# ZB204 register map
Vendor: GS; File version: 1.2
CPU: CM3 r2p0, little endian, MPU, no FPU, VTOR, 3 interrupt priority bits
Registers are 32-bit, read-write, reset 0x0 unless marked. A register's access mark holds for its fields unless they carry their own. Offsets are from the block's base; [hi:lo] are bit positions; {n}, {i} and the like mark numbered series; 'fields as' and 'values as' point back to an identical list.

## DMAC — AMBA AHB module
Base 0x40300000
0x00 IntStatus — Interrupt Status Register
  [7:0] Intstatus — Status of the DMA interrupts after masking
0x04 IntTCStatus — Interrupt Terminal Count Status Register
  [7:0] IntTCStatus — Interrupt terminal count request status
0x08 IntTCClear — Interrupt Terminal Count Clear Register
  [7:0] IntTCClear — Terminal count request clear
0x0C IntErrorStatus — Interrupt Error Status Register
  [7:0] IntErrorStatus — Interrupt error status
0x10 IntErrClr — Interrupt Error Clear Register
  [7:0] IntErrClr — Interrupt error clear
0x14 RawIntTCStatus — Raw Interrupt Terminal Count Status Register
  [7:0] RawIntTCStatus — Status of the terminal count interrupt prior to masking
0x18 RawIntErrorStatus — Raw Error Interrupt Status Register
  [7:0] RawIntErrorStatus — Status of the error interrupt prior to masking
0x1C EnbldChns — Enabled Channel Register
  [7:0] EnabledChannels — Channel enable status
0x20 SoftBReq — ADC channel selectSoftware Burst Request Registerion Register
  [15:0] SoftBReq — Software burst request
0x24 SoftSReq — Software Single Request Register
  [15:0] SoftSReq — Software single request
0x28 SoftLBReq — Software Last Burst Request Register
  [15:0] SoftLBReq — Software last burst request
0x2C SoftLSReq — Software Last Single Request Register
  [15:0] SoftLSReq — Software last single request
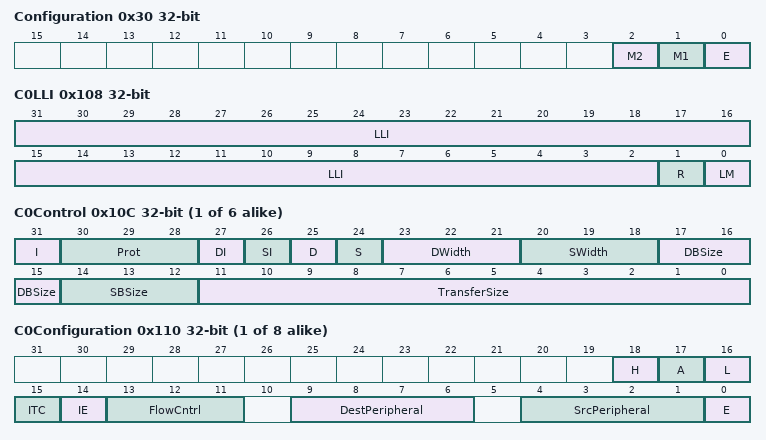
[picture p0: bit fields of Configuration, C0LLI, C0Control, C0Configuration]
0x30 Configuration
  [2] M2 — AHB Master 2 endianness configuration
  [1] M1 — AHB Master 1 endianness configuration
  [0] E — PrimeCell enable
0x34 Sync — Synchronization Register,
  [15:0] Sync — DMA synchronization logic for DMA request signals enabled or disabled
{0x100+0x20*i} C{i}SrcAddr (i=0..7) — Channel Source Address Registers,
  [31:0] SrcAddr — DMA source address
0x104 C0DestAddr — Channel Destination Address Registers,
  [31:0] DestAddr — DMA destination address
0x108 C0LLI — Channel Linked List Item Registers
  [31:2] LLI — Linked list item
  [1] R — Reserved, and must be written as 0, masked on read
  [0] LM — AHB master select for loading the next LLI
{0x10C+0x20*i} C{i}Control (i=0..5) — Channel Control Registers
  [31] I — Terminal count interrupt enable bit
  [30:28] Prot — Protection
  [27] DI — Destination increment
  [26] SI — Source increment
  [25] D — Destination AHB master select
  [24] S — Source AHB master select
  [23:21] DWidth — Destination transfer width
  [20:18] SWidth — Source transfer width
  [17:15] DBSize — Destination burst size
  [14:12] SBSize — Source burst size
  [11:0] TransferSize
{0x110+0x20*i} C{i}Configuration (i=0..7) — Channel Configuration Registers
  [18] H — Halt
  [17] A — Active
  [16] L — Lock
  [15] ITC — Terminal count interrupt mask
  [14] IE — Interrupt error mask
  [13:11] FlowCntrl — Flow control and transfer type
  [9:6] DestPeripheral — Destination peripheral
  [4:1] SrcPeripheral — Source peripheral
  [0] E — Channel enable
    0=channel disabled; 1=channel enabled
{0x104+0x20*i} C{i}DestAddr (i=1..7) — Channel Destination Address Registers
  [31:0] DestAddr — DMA destination address
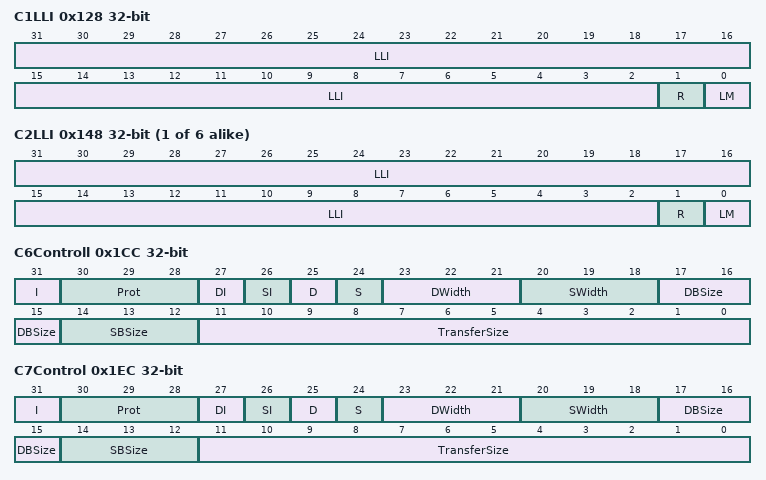
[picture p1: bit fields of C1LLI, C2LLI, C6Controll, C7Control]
0x128 C1LLI — Channel Linked List Item Registers
  [31:2] LLI — Linked list item
  [1] R — and must be written as 0, masked on read
  [0] LM — AHB master select for loading the next LLI
{0x108+0x20*i} C{i}LLI (i=2..7) — Channel Linked List Item Registers
  fields as C0LLI
0x1CC C6Controll — Channel Control Registers
  fields as C0Control
0x1EC C7Control — Channel Control Registers
  fields as C0Control
0x500 ITCR — Test Control Register
0x504 ITOP1 — Integration Test Output Register 1
0x508 ITOP2 — Integration Test Output Register 2
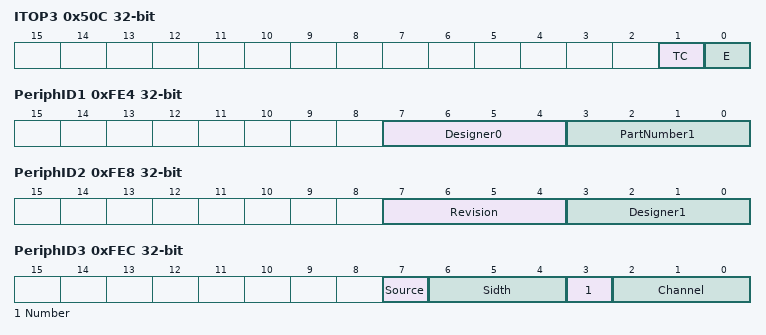
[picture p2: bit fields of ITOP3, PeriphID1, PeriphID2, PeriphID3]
0x50C ITOP3 — Integration Test Output Register 3
  [1] TC — Interrupt request can be set to a certain value in test mode by writing to the register
  [0] E — Interrupt request can be set to a certain value in test mode by writing to the register
0xFE0 PeriphID0 — Peripheral Identification Registers 0
  [7:0] PartNumber0 — These bits read back as 0x80
0xFE4 PeriphID1 — Peripheral Identification Registers 1
  [7:4] Designer0 — These bits read back as 0x1
  [3:0] PartNumber1 — These bits read back as 0x0
0xFE8 PeriphID2 — Peripheral Identification Registers 2
  [7:4] Revision — These bits read back as 0x0
  [3:0] Designer1 — These bits read back as 0x4
0xFEC PeriphID3 — Peripheral Identification Registers 3
  [7] Source — Indicates the number of DMA source requestors for the PrimeCell configuration
  [6:4] Sidth — Indicates the AHB master bus width
  [3] Number — Indicates the number of AHB masters
  [2:0] Channel — Indicates the number of channels
{0xFF0+4i} PCellID{i} (i=0..3) — PrimeCell Identification Registers 0-3,
